# ATxmega128A1 register map
Vendor: Atmel; File version: 1.0
CPU: other r0p0, little endian, no MPU, no FPU, 4 interrupt priority bits
Registers are 8-bit, read-write, reset 0x0 unless marked. A register's access mark holds for its fields unless they carry their own. Offsets are from the block's base; [hi:lo] are bit positions; {n}, {i} and the like mark numbered series; 'fields as' and 'values as' point back to an identical list.

## GPIO — General Purpose IO
Base 0x00000000
{0x0+i} GPIOR{i} (i=0..9) — General Purpose IO Register {i}
0x0A GPIORA — General Purpose IO Register 10
0x0B GPIORB — General Purpose IO Register 11
0x0C GPIORC — General Purpose IO Register 12
0x0D GPIORD — General Purpose IO Register 13
0x0E GPIORE — General Purpose IO Register 14
0x0F GPIORF — General Purpose IO Register 15

## HIRESC — 16-bit Timer/Counter With PWM
Base 0x00000890
Same registers: HIRESD 0x00000990, HIRESE 0x00000A90, HIRESF 0x00000B90
0x00 CTRLA — Control Register
  [1:0] HREN — High Resolution Enable
    0=NONE (No Fault Protection); 1=TC0 (Enable High Resolution on Timer/Counter 0); 2=TC1 (Enable High Resolution on Timer/Counter 1); 3=BOTH (Enable High Resolution both Timer/Counters)

## IRCOM — IR Communication Module
Base 0x000008F8
0x00 CTRL — Control Register
  [3:0] EVSEL — Event Channel Select
    0=OFF (No Event Source); {v}=Event Channel {v-8} (v=8..15)
0x01 TXPLCTRL — IrDA Transmitter Pulse Length Control Register
0x02 RXPLCTRL — IrDA Receiver Pulse Length Control Register

## LOCKBIT — Non Volatile Memory Controller
Base 0x00000000
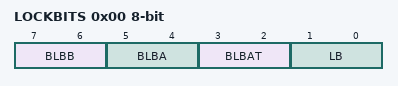
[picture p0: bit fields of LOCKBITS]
0x00 LOCKBITS
  [7:6] BLBB — Boot Lock Bits - Boot Section
    0=RWLOCK (Read and write not allowed); 1=RLOCK (Read not allowed); 2=WLOCK (Write not allowed); 3=NOLOCK (No locks)
  [5:4] BLBA — Boot Lock Bits - Application Section
    values as BLBB
  [3:2] BLBAT — Boot Lock Bits - Application Table
    values as BLBB
  [1:0] LB — Lock Bits
    0=RWLOCK (Read and write not allowed); 2=WLOCK (Write not allowed); 3=NOLOCK (No locks)

## MCU — MCU Control
Base 0x00000090
{0x0+i} DEVID{i} (i=0..2) — Device ID byte {i}
0x03 REVID — Revision ID
0x04 JTAGUID — JTAG User ID
0x06 MCUCR — MCU Control
  [0] JTAGD — JTAG Disable
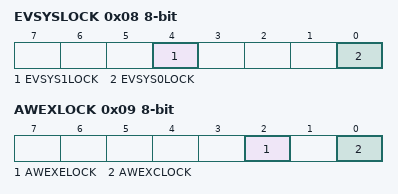
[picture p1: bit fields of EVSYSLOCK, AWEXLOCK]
0x08 EVSYSLOCK — Event System Lock
  [4] EVSYS1LOCK — Event Channel 4-7 Lock
  [0] EVSYS0LOCK — Event Channel 0-3 Lock
0x09 AWEXLOCK
  [2] AWEXELOCK — AWeX on T/C E0 Lock
  [0] AWEXCLOCK — AWeX on T/C C0 Lock

## NVM — Non Volatile Memory Controller
Base 0x000001C0
{0x0+i} ADDR{i} (i=0..2) — Address Register {i}
{0x4+i} DATA{i} (i=0..2) — Data Register {i}
0x0A CMD — Command
  [6:0] CMD
    0=NO_OPERATION (Noop/Ordinary LPM); 1=READ_USER_SIG_ROW (Read user signature row); 2=READ_CALIB_ROW (Read calibration row); 6=READ_EEPROM; 7=READ_FUSES (Read fuse byte); 8=WRITE_LOCK_BITS; 24=ERASE_USER_SIG_ROW (Erase user signature row); 26=WRITE_USER_SIG_ROW (Write user signature row); 32=ERASE_APP (Erase Application Section); 34=ERASE_APP_PAGE (Erase Application Section page); 35=LOAD_FLASH_BUFFER (Load Flash page buffer); 36=WRITE_APP_PAGE (Write Application Section page); 37=ERASE_WRITE_APP_PAGE (Erase-and-write Application Section page); 38=ERASE_FLASH_BUFFER (Erase/flush Flash page buffer); 42=ERASE_BOOT_PAGE (Erase Boot Section page); 43=ERASE_FLASH_PAGE; 44=WRITE_BOOT_PAGE (Write Boot Section page); 45=ERASE_WRITE_BOOT_PAGE (Erase-and-write Boot Section page); 46=WRITE_FLASH_PAGE; 47=ERASE_WRITE_FLASH_PAGE (Erase-and-write Flash Page); 48=ERASE_EEPROM; 50=ERASE_EEPROM_PAGE; 51=LOAD_EEPROM_BUFFER (Load EEPROM page buffer); 52=WRITE_EEPROM_PAGE; 53=ERASE_WRITE_EEPROM_PAGE (Erase-and-write EEPROM page); 54=ERASE_EEPROM_BUFFER (Erase/flush EEPROM page buffer); 56=APP_CRC (Application section CRC); 57=BOOT_CRC (Boot Section CRC); 58=FLASH_RANGE_CRC; 64=CHIP_ERASE (Erase Chip); 67=READ_NVM; 76=WRITE_FUSE (Write Fuse byte); 104=ERASE_BOOT (Erase Boot Section); 120=FLASH_CRC
0x0B CTRLA — Control Register A
  [0] CMDEX — Command Execute
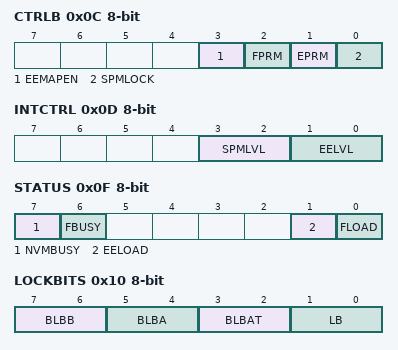
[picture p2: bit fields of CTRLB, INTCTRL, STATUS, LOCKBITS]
0x0C CTRLB — Control Register B
  [3] EEMAPEN — EEPROM Mapping Enable
  [2] FPRM — Flash Power Reduction Enable
  [1] EPRM — EEPROM Power Reduction Enable
  [0] SPMLOCK
0x0D INTCTRL — Interrupt Control
  [3:2] SPMLVL — SPM Interrupt Level
    0=OFF (Interrupt disabled); 1=LO (Low level); 2=MED (Medium level); 3=HI (High level)
  [1:0] EELVL — EEPROM Interrupt Level
    values as SPMLVL
0x0F STATUS
  [7] NVMBUSY — Non-volatile Memory Busy
  [6] FBUSY — Flash Memory Busy
  [1] EELOAD — EEPROM Page Buffer Active Loading
  [0] FLOAD — Flash Page Buffer Active Loading
0x10 LOCKBITS
  [7:6] BLBB — Boot Lock Bits - Boot Section
    0=RWLOCK (Read and write not allowed); 1=RLOCK (Read not allowed); 2=WLOCK (Write not allowed); 3=NOLOCK (No locks)
  [5:4] BLBA — Boot Lock Bits - Application Section
    values as BLBB
  [3:2] BLBAT — Boot Lock Bits - Application Table
    values as BLBB
  [1:0] LB — Lock Bits
    0=RWLOCK (Read and write not allowed); 2=WLOCK (Write not allowed); 3=NOLOCK (No locks)
